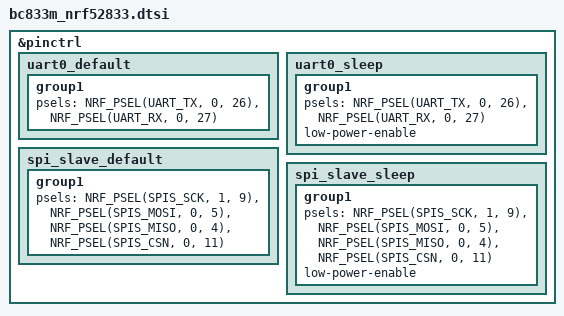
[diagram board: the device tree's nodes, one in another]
&pinctrl {

    uart0_default: uart0_default {
        group1 {
            psels = <NRF_PSEL(UART_TX, 0, 26)>,
                    <NRF_PSEL(UART_RX, 0, 27)>;
        };
    };

    uart0_sleep: uart0_sleep {
        group1 {
            psels = <NRF_PSEL(UART_TX, 0, 26)>,
                    <NRF_PSEL(UART_RX, 0, 27)>;
            low-power-enable;
        };
    };

    spi_slave_default: spi_slave_default {
		group1 {
			psels = <NRF_PSEL(SPIS_SCK, 1, 9)>,
					<NRF_PSEL(SPIS_MOSI, 0, 5)>,
					<NRF_PSEL(SPIS_MISO, 0, 4)>,
					<NRF_PSEL(SPIS_CSN, 0, 11)>;
		};
	};

	spi_slave_sleep: spi_slave_sleep {
		group1 {
			psels = <NRF_PSEL(SPIS_SCK, 1, 9)>,
					<NRF_PSEL(SPIS_MOSI, 0, 5)>,
					<NRF_PSEL(SPIS_MISO, 0, 4)>,
					<NRF_PSEL(SPIS_CSN, 0, 11)>;
            low-power-enable;
		};
	};
};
